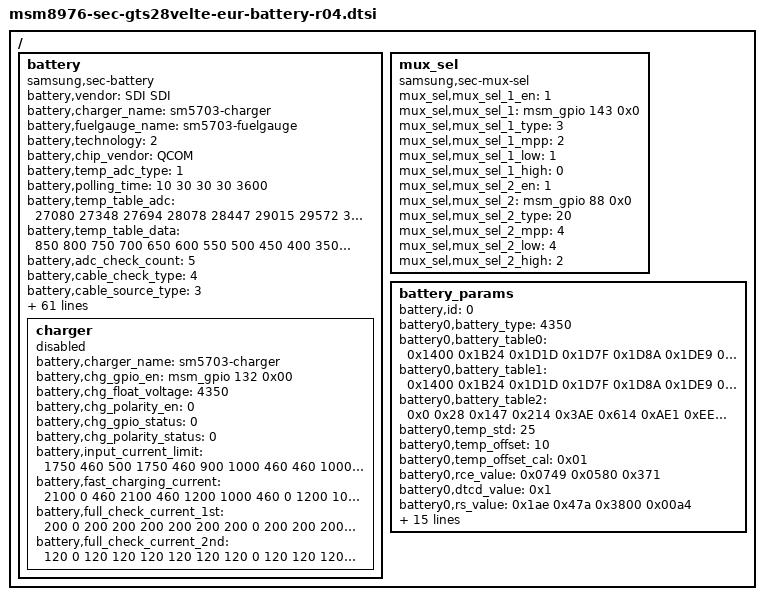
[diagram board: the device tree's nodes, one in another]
/* Copyright (c) 2016, The Linux Foundation. All rights reserved.
 *
 * This program is free software; you can redistribute it and/or modify
 * it under the terms of the GNU General Public License version 2 and
 * only version 2 as published by the Free Software Foundation.
 *
 * This program is distributed in the hope that it will be useful,
 * but WITHOUT ANY WARRANTY; without even the implied warranty of
 * MERCHANTABILITY or FITNESS FOR A PARTICULAR PURPOSE.  See the
 * GNU General Public License for more details.
 */

/ {
	battery {
		status = "okay";
		compatible = "samsung,sec-battery";
		battery,vendor = "SDI SDI";
		battery,charger_name = "sm5703-charger";
		battery,fuelgauge_name = "sm5703-fuelgauge";
		battery,technology = <2>; /* POWER_SUPPLY_TECHNOLOGY_LION */

		battery,chip_vendor = "QCOM";
		battery,temp_adc_type = <1>; /* SEC_BATTERY_ADC_TYPE_AP */

		battery,polling_time = <10 30 30 30 3600>;

		battery,temp_table_adc = <27080 27348 27694 28078 28447 29015 29572 30140 30788 31503 32272
						33094 33938 34799 35725 36593 37430 38232 38986 39727 40337 40850>;

		battery,temp_table_data = <850 800 750 700 650 600 550 500 450 400 350
						300 250 200 150 100 50 0 (-50) (-100) (-150) (-200)>;

		battery,adc_check_count = <5>;

		battery,cable_check_type = <4>; /* SEC_BATTERY_CABLE_CHECK_PSY */
		battery,cable_source_type = <3>; /* SEC_BATTERY_CABLE_SOURCE_EXTERNAL */
		battery,event_waiting_time = <600>;
		battery,polling_type = <1>; /* SEC_BATTERY_MONITOR_ALARM */
		battery,monitor_initial_count = <3>;

		battery,battery_check_type = <0>; /* SEC_BATTERY_CHECK_NONE */
		battery,check_count = <0>;
		battery,check_adc_max = <1440000>;
		battery,check_adc_min = <0>;

		battery,ovp_uvlo_check_type = <3>; /* SEC_BATTERY_OVP_UVLO_CHGPOLLING */

		battery,thermal_source = <2>; /* SEC_BATTERY_THERMAL_SOURCE_ADC */

		battery,temp_check_type = <2>; /* SEC_BATTERY_TEMP_CHECK_TEMP */
		battery,temp_check_count = <1>;
		battery,temp_highlimit_threshold_event = <800>;
		battery,temp_highlimit_recovery_event = <750>;
		battery,temp_high_threshold_event = <550>;
		battery,temp_high_recovery_event = <500>;
		battery,temp_low_threshold_event = <(-50)>;
		battery,temp_low_recovery_event = <0>;
		battery,temp_highlimit_threshold_normal = <800>;
		battery,temp_highlimit_recovery_normal = <750>;
		battery,temp_high_threshold_normal = <550>;
		battery,temp_high_recovery_normal = <500>;
		battery,temp_low_threshold_normal = <(-50)>;
		battery,temp_low_recovery_normal = <0>;
		battery,temp_highlimit_threshold_lpm = <800>;
		battery,temp_highlimit_recovery_lpm = <750>;
		battery,temp_high_threshold_lpm = <550>;
		battery,temp_high_recovery_lpm = <500>;
		battery,temp_low_threshold_lpm = <(-50)>;
		battery,temp_low_recovery_lpm = <0>;
		battery,full_check_type = <2>; /* SEC_BATTERY_FULLCHARGED_FG_CURRENT */
		battery,full_check_type_2nd = <2>; /* SEC_BATTERY_FULLCHARGED_FG_CURRENT */
		battery,full_check_count = <1>;
		battery,chg_gpio_full_check = <0>;
		battery,chg_polarity_full_check = <1>;

		/* SEC_BATTERY_FULL_CONDITION_SOC |
		   SEC_BATTERY_FULL_CONDITION_NOTIMEFULL |
		   SEC_BATTERY_FULL_CONDITION_VCELL */
		battery,full_condition_type = <13>;
		battery,full_condition_soc = <93>;
		battery,full_condition_vcell = <4250>;

		battery,recharge_check_count = <1>;
		battery,recharge_condition_type = <4>; /* SEC_BATTERY_RECHARGE_CONDITION_VCELL */
		battery,recharge_condition_soc = <98>;
		battery,recharge_condition_vcell = <4280>;

		battery,charging_total_time = <21600>;
		battery,recharging_total_time = <5400>;
		battery,charging_reset_time = <0>;

		battery,swelling_high_temp_block = <450>;
		battery,swelling_high_temp_recov = <400>;
		battery,swelling_low_temp_block = <100>;
		battery,swelling_low_temp_recov = <150>;
		//battery,swelling_chg_current = <1500>;
		battery,swelling_high_chg_current = <2100>;
		battery,swelling_low_chg_current = <1950>;
		battery,swelling_full_check_current_2nd = <200>;
		battery,swelling_drop_float_voltage = <4150>;
		battery,swelling_high_rechg_voltage = <4000>;
		battery,swelling_low_rechg_voltage = <4000>;

		battery,self_discharging_temp_block = <600>;
		battery,self_discharging_volt_block = <4250>;
		battery,self_discharging_temp_recov = <550>;
		battery,self_discharging_temp_pollingtime = <400>;

		qcom,sec-battery-vadc = <&pm8950_vadc>;

		/* cycle, chg_float_voltage, recharge_condition_vcell, full_condition_vcell, full_condition_soc */
		battery,age_data = <
				0 4350 4280 4250 93
				200 4330 4260 4230 92
				250 4310 4240 4210 91
				300 4290 4220 4190 90
				1000 4240 4170 4140 89
				>;

		charger {
			status = "disable";
			/* Charger */
			battery,charger_name = "sm5703-charger";
			battery,chg_gpio_en = <&msm_gpio 132 0x00>;
			battery,chg_float_voltage = <4350>;

			battery,chg_polarity_en = <0>;
			battery,chg_gpio_status = <0>;
			battery,chg_polarity_status = <0>;

			battery,input_current_limit = <1750 460 500 1750 460 900 1000 460 460 1000 820 1700 1700 460 1300 300 700 1300 1500 300 80 900 1500 1000 1000 1650 1650 1650 1400 900 820 820 900 1000 1000>;
			battery,fast_charging_current = <2100 0 460 2100 460 1200 1000 460 0 1200 1000 2100 2100 0 1300 300 700 1300 1500 300 80 1200 1500 1000 1000 2750 1000 2750 1400 1200 1000 1000 1200 0 1000>;
			battery,full_check_current_1st = <200 0 200 200 200 200 200 200 0 200 200 200 200 0 200 200 200 200 200 200 200 200 0 200 200 200 200 200 200 200 200 200 200 0 200>;
			battery,full_check_current_2nd = <120 0 120 120 120 120 120 120 0 120 120 120 120 0 120 120 120 120 120 120 120 120 0 120 120 120 120 120 120 120 120 120 120 0 120>;
		};
	};

	mux_sel {
		compatible = "samsung,sec-mux-sel";
		mux_sel,mux_sel_1_en = <1>;
		mux_sel,mux_sel_1 = <&msm_gpio 143 0x0>;
		mux_sel,mux_sel_1_type = <3>; /* EAR_ADC_MUX_SEL | BATT_ID_MUX_SEL */
		mux_sel,mux_sel_1_mpp = <2>; /* SEC_MPP2_MUX_SEL */
		mux_sel,mux_sel_1_low = <1>; /* SEC_MUX_SEL_BATT_ID */
		mux_sel,mux_sel_1_high = <0>; /* SEC_MUX_SEL_EAR_ADC */

		mux_sel,mux_sel_2_en = <1>;
		mux_sel,mux_sel_2 = <&msm_gpio 88 0x0>;
		mux_sel,mux_sel_2_type = <20>; /* BATT_THM_MUX_SEL | AP_THM_MUX_SEL */
		mux_sel,mux_sel_2_mpp = <4>; /* SEC_MPP4_MUX_SEL */
		mux_sel,mux_sel_2_low = <4>; /* SEC_MUX_SEL_AP_THM */
		mux_sel,mux_sel_2_high = <2>; /* SEC_MUX_SEL_BATT_THM */
	};

	battery_params {
		battery,id = <0>; /* -1 means auto, detected by F/G */
		battery0,battery_type = <4350>; /* 4200 4350 4400 */
		battery0,battery_table0 = <0x1400 0x1B24 0x1D1D 0x1D7F 0x1D8A 0x1DE9 0x1E5A 0x1EBD 0x1F16 0x1FB4 0x1FF4 0x208F 0x20AA 0x2148 0x224C 0x2400>;
		battery0,battery_table1 = <0x1400 0x1B24 0x1D1D 0x1D7F 0x1D8A 0x1DE9 0x1E5A 0x1EBD 0x1F16 0x1FB4 0x1FF4 0x208F 0x20AA 0x2148 0x224C 0x2400>;
		battery0,battery_table2 = <0x0 0x28 0x147 0x214 0x3AE 0x614 0xAE1 0xEE1 0x1147 0x13AE 0x1547 0x16E1 0x17AE 0x1A14 0x1D99 0x1DA8>;
		battery0,temp_std = <25>;
		battery0,temp_offset = <10>;
		battery0,temp_offset_cal = <0x01>;
		battery0,rce_value = <0x0749 0x0580 0x371>;
		battery0,dtcd_value = <0x1>;
		battery0,rs_value = <0x1ae 0x47a 0x3800 0x00a4>; /*rs mix_factor max min*/
		battery0,vit_period = <0x3506>;
		battery0,mix_value = <0x0503 0x0004>; /*mix_rate init_blank*/
		battery0,topoff_soc = <0x0 0x5>; /*enable soc*/
		battery0,tem_poff = <3400 50 3350 50>;
		battery0,charge_offset_cal = <0x01>;
		battery0,min_charge_curr = <300>;
		battery0,volt_cal = <0x809E>;
		battery0,curr_cal = <0x7385>;
		battery0,ext_temp_cal = <0 10 1 1 1 7 1 2>;
		battery0,v_alarm = <3250>;
		battery0,v_max_table = <0x224C 0x2225 0x21FE 0x21D7 0x2174>;
		battery0,q_max_table = <0x1D99 0x1D13 0x1C8D 0x1C07 0x1AB8>;
		battery0,data_ver = <0x02>;
	};
};
